# f28p551x_adc_result_regs register map
Vendor: Texas Instruments
Peripheral module from a debugger description file (folder C2000).
Address unit: 16 bits
Registers are 16-bit, read-only, no defined reset value unless marked. A register's access mark holds for its fields unless they carry their own. Offsets are as the file gives them; lines under a group give offsets from that group; [hi:lo] are bit positions; {n}, {i} and the like mark numbered series; 'fields as' and 'values as' point back to an identical list; <NAME> marks a mode.

## ADC_RESULT_REGS — ADC RESULT Registers
{0x0+i} ADCRESULT{i} (i=0..15)
  [15:0] RESULT — ADC Result
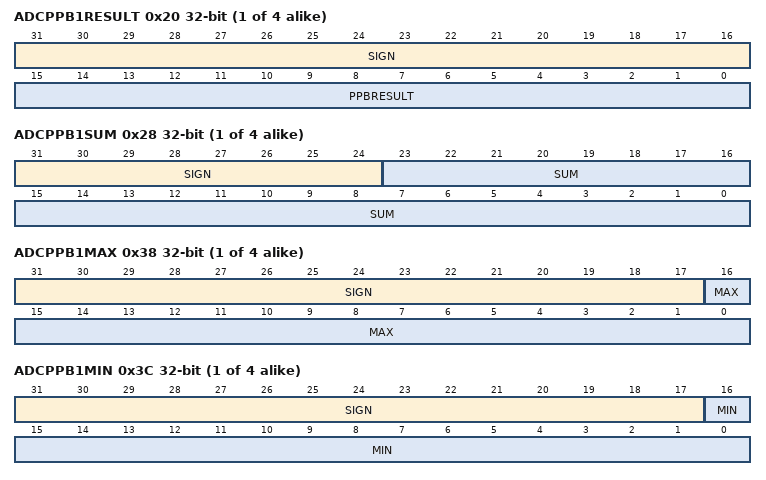
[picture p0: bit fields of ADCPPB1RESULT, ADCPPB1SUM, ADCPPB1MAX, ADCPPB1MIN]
{0x1E+2i} ADCPPB{i}RESULT 32-bit (i=1..4) — ADC Post Processing Block {i} Result Register
  [31:16] SIGN — Sign Extended Bits
  [15:0] PPBRESULT — ADC Post Processing Block Result
{0x24+4i} ADCPPB{i}SUM 32-bit (i=1..4) — ADC PPB {i} Final Sum Result Register
  [31:24] SIGN — Sign Extended Bits
  [23:0] SUM — Post Processing Block {i} Oversampling Sum
{0x26+4i} ADCPPB{i}COUNT (i=1..4) — ADC PPB{i} Final Conversion Count Register
  [9:0] COUNT — Post Processing Block {i} Final Count
{0x30+8i} ADCPPB{i}MAX 32-bit (i=1..4) — ADC PPB {i} Final Max Result Register
  [31:17] SIGN — Sign Extended Bits
  [16:0] MAX — Post Processing Block {i} Oversampling Max
{0x32+8i} ADCPPB{i}MAXI (i=1..4) — ADC PPB {i} Final Max Index Result Register
  [9:0] MAXI — Post Processing Block {i} Oversampling Index of Max
{0x34+8i} ADCPPB{i}MIN 32-bit (i=1..4) — ADC PPB {i} Final Min Result Register
  [31:17] SIGN — Sign Extended Bits
  [16:0] MIN — Post Processing Block {i} Oversampling Min
{0x36+8i} ADCPPB{i}MINI (i=1..4) — ADC PPB {i} Final Min Index Result Register
  [9:0] MINI — Post Processing Block {i} Oversampling Index of Min
